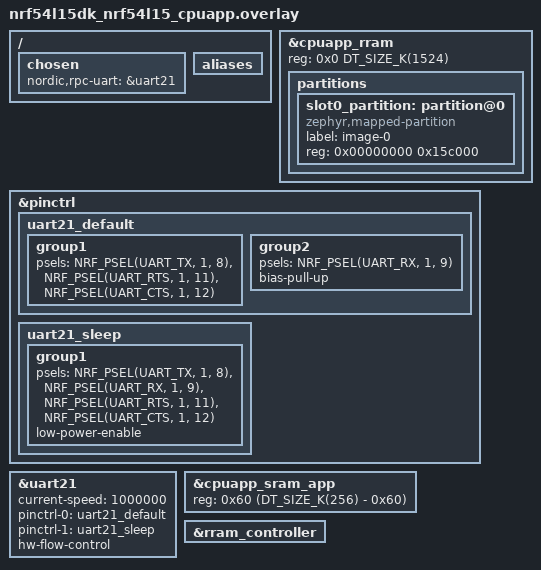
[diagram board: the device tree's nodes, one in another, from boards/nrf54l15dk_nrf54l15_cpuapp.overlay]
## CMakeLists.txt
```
#
# Copyright (c) 2024 Nordic Semiconductor ASA
#
# SPDX-License-Identifier: LicenseRef-Nordic-5-Clause
#
cmake_minimum_required(VERSION 3.20.0)

find_package(Zephyr REQUIRED HINTS $ENV{ZEPHYR_BASE})

project(protocols_serialization_client)

# NORDIC SDK APP START
target_sources(app PRIVATE
    src/main.c
)

zephyr_library_sources_ifdef(CONFIG_OPENTHREAD_RPC src/ot_shell.c)
zephyr_library_sources_ifdef(CONFIG_MPSL_CX_SOFTWARE src/coex_shell.c)
zephyr_library_sources_ifdef(CONFIG_LOG_FORWARDER_RPC src/log_rpc_shell.c)
zephyr_library_sources_ifdef(CONFIG_NFC_RPC src/nfc_shell.c)
zephyr_library_sources_ifdef(CONFIG_BT_THROUGHPUT src/bt_throughput_shell.c)
zephyr_library_sources_ifdef(CONFIG_NRF_RPC_UTILS src/rpc_utils_shell.c)
zephyr_library_sources_ifdef(CONFIG_NRF_PS_CLIENT_BT_TEST src/bt_test_shell.c)
# NORDIC SDK APP END
```

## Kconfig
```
#
# Copyright (c) 2024 Nordic Semiconductor ASA
#
# SPDX-License-Identifier: LicenseRef-Nordic-5-Clause
#

menu "Protocols serialization client"

config NRF_PS_CLIENT_CRASH_DUMP_READ_BUFFER_SIZE
	int "Crash log read buffer size"
	depends on LOG_FORWARDER_RPC
	default 256
	help
	  Size of the stack buffer used for reading a single chunk of the crash
	  log from the server device.

module = NRF_PS_CLIENT
module-str = nrf_ps_client
source "$(ZEPHYR_BASE)/subsys/logging/Kconfig.template.log_config"

config NRF_PS_CLIENT_BT_TEST
	bool "BLE test service for RPC Client"
	depends on BT
	help
	 Enable BLE test service for RPC Client.

if NRF_PS_CLIENT_BT_TEST

config NRF_PS_CLIENT_BT_TEST_CHAR_MAX_DATA_SIZE
	int "Maximum size of BLE test characteristic data in bytes"
	default 4

endif # NRF_PS_CLIENT_BT_TEST

endmenu # "Protocols serialization client"

if SETTINGS

config ZMS
	default y if (SOC_FLASH_NRF_RRAM || SOC_FLASH_NRF_MRAM)

config NVS
	default y if !(SOC_FLASH_NRF_RRAM || SOC_FLASH_NRF_MRAM)

endif # SETTINGS

menu "Zephyr Kernel"
source "Kconfig.zephyr"
endmenu
```

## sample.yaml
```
sample:
  name: Protocols serialization client sample
  description: Demonstrates serialization of Bluetooth LE and OpenThread API using
    nRF RPC

common:
  sysbuild: true
  build_only: true
  platform_allow:
    - nrf54l15dk/nrf54l15/cpuapp
    - nrf54lm20dk/nrf54lm20a/cpuapp
    - nrf54lm20dk/nrf54lm20b/cpuapp
  integration_platforms:
    - nrf54l15dk/nrf54l15/cpuapp
    - nrf54lm20dk/nrf54lm20a/cpuapp
    - nrf54lm20dk/nrf54lm20b/cpuapp
  tags:
    - ci_build
    - ci_samples_nrf_rpc
  extra_args:
    - SNIPPET_ROOT="."

tests:
  sample.nrf_rpc.protocols_serialization.client.rpc_ble:
    extra_args:
      - EXTRA_CONF_FILE=ble.conf
  sample.nrf_rpc.protocols_serialization.client.rpc_ot:
    extra_args:
      - EXTRA_CONF_FILE=openthread.conf
  sample.nrf_rpc.protocols_serialization.client.rpc:
    extra_args:
      - EXTRA_DTC_OVERLAY_FILE=coex.overlay
      - EXTRA_CONF_FILE="ble.conf;openthread.conf;verbose.conf;log_rpc.conf;coex.conf"
  sample.nrf_rpc.protocols_serialization.client.rpc_ci:
    extra_args:
      - SNIPPET="ci-shell;zperf"
      - EXTRA_DTC_OVERLAY_FILE=coex.overlay
      - EXTRA_CONF_FILE="ble.conf;openthread.conf;log_rpc.conf;coex.conf"
    extra_configs:
      - CONFIG_NRF_RPC_UTILS_CRASH_GEN=y
```

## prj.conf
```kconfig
#
# Copyright (c) 2024 Nordic Semiconductor
#
# SPDX-License-Identifier: LicenseRef-Nordic-5-Clause
#
CONFIG_HEAP_MEM_POOL_SIZE=4096

CONFIG_NRF_RPC=y
CONFIG_NRF_RPC_CBOR=y
CONFIG_NRF_RPC_ZCBOR_BACKUPS=1
CONFIG_NRF_RPC_THREAD_STACK_SIZE=4096
CONFIG_NRF_RPC_GROUP_INIT_WAIT_TIME=-1
CONFIG_NRF_RPC_UART_TRANSPORT=y
CONFIG_NRF_RPC_UART_RELIABLE=y

CONFIG_UART_LINE_CTRL=y
CONFIG_UART_INTERRUPT_DRIVEN=y

CONFIG_SHELL=y
CONFIG_SHELL_STACK_SIZE=3072
CONFIG_LOG=y
CONFIG_LOG_MODE_DEFERRED=y
CONFIG_LOG_BUFFER_SIZE=8192
CONFIG_LOG_FUNC_NAME_PREFIX_DBG=n
CONFIG_LOG_BACKEND_RTT=n
CONFIG_SHELL_LOG_BACKEND=y

CONFIG_NRF_RPC_UTILS=y
CONFIG_NRF_RPC_UTILS_CLIENT=y
CONFIG_NRF_RPC_UTILS_DEV_INFO=y
CONFIG_NRF_RPC_UTILS_REMOTE_SHELL=y
CONFIG_NRF_RPC_UTILS_SYSTEM_HEALTH=y
CONFIG_NRF_RPC_UTILS_NESTED_CMD_TEST=y

CONFIG_USE_DT_CODE_PARTITION=y
```

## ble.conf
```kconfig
#
# Copyright (c) 2024 Nordic Semiconductor ASA
#
# SPDX-License-Identifier: LicenseRef-Nordic-5-Clause
#

CONFIG_SYSTEM_WORKQUEUE_STACK_SIZE=2144

# Enable and configure Bluetooth LE
CONFIG_BT=y
CONFIG_BT_RPC_STACK=y
CONFIG_NRF_RPC_INIT=n
CONFIG_BT_RPC_GATT_SRV_MAX=4
CONFIG_BT_PERIPHERAL=y
CONFIG_BT_MAX_CONN=1
CONFIG_BT_LL_SOFTDEVICE=n
CONFIG_BT_SHELL=y

# Device name and appearance shall be the same as on the server side
CONFIG_BT_DEVICE_NAME="Nordic_PS"

# Enable the NUS service
CONFIG_BT_NUS=y
CONFIG_BT_NUS_LOG_LEVEL_DBG=y

# Enable the Latency service
CONFIG_BT_LATENCY=y
CONFIG_BT_LATENCY_LOG_LEVEL_DBG=y

# Enable the Test service
CONFIG_NRF_PS_CLIENT_BT_TEST=y

# Enable the Throughput service
CONFIG_BT_THROUGHPUT=y
CONFIG_BT_THROUGHPUT_LOG_LEVEL_DBG=y

# Enable SMP that is required by the Throughput service.
CONFIG_SETTINGS=y
CONFIG_FLASH=y
CONFIG_FLASH_MAP=y
CONFIG_BT_SETTINGS=y
CONFIG_BT_SMP=y

# Disable HCI-based entropy driver (unavailable for BT_RPC_STACK)
CONFIG_ENTROPY_BT_HCI=n
```

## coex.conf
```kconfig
#
# Copyright (c) 2024 Nordic Semiconductor ASA
#
# SPDX-License-Identifier: LicenseRef-Nordic-5-Clause
#

CONFIG_MPSL_CX=y
CONFIG_MPSL_CX_SOFTWARE=y
```

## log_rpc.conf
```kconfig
#
# Copyright (c) 2024 Nordic Semiconductor ASA
#
# SPDX-License-Identifier: LicenseRef-Nordic-5-Clause
#

CONFIG_LOG_FORWARDER_RPC=y
```

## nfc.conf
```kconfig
#
# Copyright (c) 2024 Nordic Semiconductor ASA
#
# SPDX-License-Identifier: LicenseRef-Nordic-5-Clause
#

CONFIG_NFC_RPC=y
CONFIG_NFC_RPC_CLIENT=y

CONFIG_NFC_NDEF=y
CONFIG_NFC_NDEF_MSG=y
CONFIG_NFC_NDEF_RECORD=y
CONFIG_NFC_NDEF_TEXT_RECORD=y
```

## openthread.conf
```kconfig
#
# Copyright (c) 2024 Nordic Semiconductor ASA
#
# SPDX-License-Identifier: LicenseRef-Nordic-5-Clause
#

CONFIG_OPENTHREAD_RPC=y
CONFIG_OPENTHREAD_RPC_CLIENT=y
CONFIG_OPENTHREAD_MESH_DIAG=y

CONFIG_NETWORKING=y
CONFIG_NET_IF_UNICAST_IPV6_ADDR_COUNT=6

# Enable networking shell to test the network interface operation
CONFIG_NET_SHELL=y
```

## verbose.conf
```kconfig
#
# Copyright (c) 2024 Nordic Semiconductor ASA
#
# SPDX-License-Identifier: LicenseRef-Nordic-5-Clause
#
# Development-oriented options: asserts and DBG log levels for this sample and
# nRF RPC modules. For manual use, pass e.g.:
#   -- -DEXTRA_CONF_FILE=verbose.conf

# Enable asserts
CONFIG_ASSERT=y

# Enable verbose logging
CONFIG_NRF_PS_CLIENT_LOG_LEVEL_DBG=y
CONFIG_NRF_RPC_TR_LOG_LEVEL_DBG=y
CONFIG_NRF_RPC_LOG_LEVEL_DBG=y
CONFIG_NRF_RPC_OS_LOG_LEVEL_DBG=y
CONFIG_NRF_RPC_DETAILED_ERROR_REPORTING=y
CONFIG_NRF_RPC_UTILS_RRAM_WEAR_TEST=y
```

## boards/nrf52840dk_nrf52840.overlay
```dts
/* Copyright (c) 2024 Nordic Semiconductor ASA
 *
 * SPDX-License-Identifier: LicenseRef-Nordic-5-Clause
 */

/ {
	chosen {
		nordic,rpc-uart = &uart1;
	};
};

/delete-node/ &boot_partition;
/delete-node/ &slot0_partition;
/delete-node/ &slot1_partition;

&flash0 {
	partitions {
		slot0_partition: partition@0 {
			compatible = "zephyr,mapped-partition";
			label = "image-0";
			reg = <0x00000000 0xf8000>;
		};
	};
};

&uart1 {
	status = "okay";
	hw-flow-control;
	current-speed = <1000000>;
};

&uart1_default {
	group1 {
		psels = <NRF_PSEL(UART_TX, 1, 2)>,
			<NRF_PSEL(UART_RTS, 1, 3)>,
			<NRF_PSEL(UART_CTS, 1, 4)>;
	};

	group2 {
		psels = <NRF_PSEL(UART_RX, 1, 1)>;
		bias-pull-up;
	};
};

&uart1_sleep {
	group1 {
		psels = <NRF_PSEL(UART_RX, 1, 1)>,
			<NRF_PSEL(UART_TX, 1, 2)>,
			<NRF_PSEL(UART_RTS, 1, 3)>,
			<NRF_PSEL(UART_CTS, 1, 4)>;
		low-power-enable;
	};
};
```

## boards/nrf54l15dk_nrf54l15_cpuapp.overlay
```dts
/* Copyright (c) 2024 Nordic Semiconductor ASA
 *
 * SPDX-License-Identifier: LicenseRef-Nordic-5-Clause
 */

/ {
	chosen {
		nordic,rpc-uart = &uart21;
	};

	/* delete all buttons except button0 to free GPIO pins assigned to uart21 below */
	aliases {
		/delete-property/ sw1;
		/delete-property/ sw2;
		/delete-property/ sw3;
	};
};

/delete-node/ &button1;
/delete-node/ &button2;
/delete-node/ &button3;
/delete-node/ &boot_partition;
/delete-node/ &slot0_partition;
/delete-node/ &slot1_partition;

/* restore full RRAM and SRAM space - by default some parts are dedicated to FLRP */
&cpuapp_rram {
	reg = <0x0 DT_SIZE_K(1524)>;

	partitions {
		slot0_partition: partition@0 {
			compatible = "zephyr,mapped-partition";
			label = "image-0";
			reg = <0x00000000 0x15c000>;
		};
	};
};

&pinctrl {
	uart21_default: uart21_default {
		group1 {
			psels = <NRF_PSEL(UART_TX, 1, 8)>,
				<NRF_PSEL(UART_RTS, 1, 11)>,
				<NRF_PSEL(UART_CTS, 1, 12)>;
		};

		group2 {
			psels = <NRF_PSEL(UART_RX, 1, 9)>;
			bias-pull-up;
		};
	};

	uart21_sleep: uart21_sleep {
		group1 {
			psels = <NRF_PSEL(UART_TX, 1, 8)>,
				<NRF_PSEL(UART_RX, 1, 9)>,
				<NRF_PSEL(UART_RTS, 1, 11)>,
				<NRF_PSEL(UART_CTS, 1, 12)>;
			low-power-enable;
		};
	};
};

&uart21 {
	status = "okay";
	current-speed = <1000000>;
	pinctrl-0 = <&uart21_default>;
	pinctrl-1 = <&uart21_sleep>;
	pinctrl-names = "default", "sleep";
	hw-flow-control;
};

&cpuapp_sram_app {
	reg = <0x60 (DT_SIZE_K(256) - 0x60)>;
};

&rram_controller {
	/delete-node/ cpuflpr_sram;
	/delete-node/ cpuflpr_rram;
};
```

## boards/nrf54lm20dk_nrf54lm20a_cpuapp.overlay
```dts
/* Copyright (c) 2025 Nordic Semiconductor ASA
 *
 * SPDX-License-Identifier: LicenseRef-Nordic-5-Clause
 */

/ {
	chosen {
		nordic,rpc-uart = &uart21;
	};

	/* delete all buttons except button0 to free GPIO pins assigned to uart21 below */
	aliases {
		/delete-property/ sw1;
		/delete-property/ sw2;
		/delete-property/ sw3;
	};
};

/delete-node/ &button1;
/delete-node/ &button2;
/delete-node/ &button3;
/delete-node/ &boot_partition;
/delete-node/ &slot0_partition;
/delete-node/ &slot1_partition;

&cpuapp_rram {
	reg = <0x0 DT_SIZE_K(2036)>;

	partitions {
		slot0_partition: partition@0 {
			compatible = "zephyr,mapped-partition";
			label = "image-0";
			reg = <0x00000000 0x1dc000>;
		};
	};
};

&pinctrl {
	uart21_default: uart21_default {
		group1 {
			psels = <NRF_PSEL(UART_TX, 1, 8)>,
				<NRF_PSEL(UART_RTS, 1, 11)>,
				<NRF_PSEL(UART_CTS, 1, 12)>;
		};

		group2 {
			psels = <NRF_PSEL(UART_RX, 1, 9)>;
			bias-pull-up;
		};
	};

	uart21_sleep: uart21_sleep {
		group1 {
			psels = <NRF_PSEL(UART_TX, 1, 8)>,
				<NRF_PSEL(UART_RX, 1, 9)>,
				<NRF_PSEL(UART_RTS, 1, 11)>,
				<NRF_PSEL(UART_CTS, 1, 12)>;
			low-power-enable;
		};
	};
};

&uart21 {
	status = "okay";
	current-speed = <1000000>;
	pinctrl-0 = <&uart21_default>;
	pinctrl-1 = <&uart21_sleep>;
	pinctrl-names = "default", "sleep";
	hw-flow-control;
};
```

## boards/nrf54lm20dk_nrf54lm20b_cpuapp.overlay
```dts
/* Copyright (c) 2026 Nordic Semiconductor ASA
 *
 * SPDX-License-Identifier: LicenseRef-Nordic-5-Clause
 */

/ {
	chosen {
		nordic,rpc-uart = &uart21;
	};

	/* delete all buttons except button0 to free GPIO pins assigned to uart21 below */
	aliases {
		/delete-property/ sw1;
		/delete-property/ sw2;
		/delete-property/ sw3;
	};
};

/delete-node/ &button1;
/delete-node/ &button2;
/delete-node/ &button3;
/delete-node/ &boot_partition;
/delete-node/ &slot0_partition;
/delete-node/ &slot1_partition;

&cpuapp_rram {
	reg = <0x0 DT_SIZE_K(2036)>;

	partitions {
		slot0_partition: partition@0 {
			label = "image-0";
			reg = <0x00000000 0x1dc000>;
		};
	};
};

&pinctrl {
	uart21_default: uart21_default {
		group1 {
			psels = <NRF_PSEL(UART_TX, 1, 8)>,
				<NRF_PSEL(UART_RTS, 1, 11)>,
				<NRF_PSEL(UART_CTS, 1, 12)>;
		};

		group2 {
			psels = <NRF_PSEL(UART_RX, 1, 9)>;
			bias-pull-up;
		};
	};

	uart21_sleep: uart21_sleep {
		group1 {
			psels = <NRF_PSEL(UART_TX, 1, 8)>,
				<NRF_PSEL(UART_RX, 1, 9)>,
				<NRF_PSEL(UART_RTS, 1, 11)>,
				<NRF_PSEL(UART_CTS, 1, 12)>;
			low-power-enable;
		};
	};
};

&uart21 {
	status = "okay";
	current-speed = <1000000>;
	pinctrl-0 = <&uart21_default>;
	pinctrl-1 = <&uart21_sleep>;
	pinctrl-names = "default", "sleep";
	hw-flow-control;
};
```

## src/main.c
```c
/*
 * Copyright (c) 2024 Nordic Semiconductor ASA
 *
 * SPDX-License-Identifier: LicenseRef-Nordic-5-Clause
 */

#include "ot_shell.h"

#include <zephyr/logging/log.h>

#include <nrf_rpc.h>

LOG_MODULE_REGISTER(nrf_ps_client, CONFIG_NRF_PS_CLIENT_LOG_LEVEL);
NRF_RPC_GROUP_DECLARE(ot_group);
NRF_RPC_GROUP_DECLARE(bt_rpc_grp);

static void err_handler(const struct nrf_rpc_err_report *report)
{
	LOG_ERR("nRF RPC error %d ocurred. See nRF RPC logs for more details", report->code);
}

static void bound_handler(const struct nrf_rpc_group *group)
{
#ifdef CONFIG_OPENTHREAD_RPC_CLIENT
	static bool ot_group_initialized;

	if (group == &ot_group) {
		if (ot_group_initialized) {
			LOG_WRN("OT RPC peer reset detected");
			ot_shell_server_restarted();
			/* The code to restore the state of OT on the server can be added here */
		} else {
			ot_group_initialized = true;
		}
	}
#endif
#ifdef CONFIG_BT_RPC_CLIENT
	static bool bt_group_initialized;

	if (group == &bt_rpc_grp) {
		if (bt_group_initialized) {
			LOG_WRN("BT RPC peer reset detected");
			/* The code to restore the state of BT on the server can be added here */
		} else {
			bt_group_initialized = true;
		}
	}
#endif
}

int main(void)
{
	int ret;

	LOG_INF("Initializing RPC client");

	nrf_rpc_set_bound_handler(bound_handler);

	ret = nrf_rpc_init(err_handler);

	if (ret != 0) {
		LOG_ERR("RPC init failed");
	}

	LOG_INF("RPC client ready");

	return 0;
}
```

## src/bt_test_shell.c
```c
/*
 * Copyright (c) 2025 Nordic Semiconductor ASA
 *
 * SPDX-License-Identifier: LicenseRef-Nordic-5-Clause
 */

#include <errno.h>
#include <stddef.h>
#include <zephyr/bluetooth/bluetooth.h>
#include <zephyr/bluetooth/conn.h>
#include <zephyr/bluetooth/gap.h>
#include <zephyr/bluetooth/gatt.h>
#include <zephyr/bluetooth/hci.h>
#include <zephyr/bluetooth/uuid.h>
#include <zephyr/shell/shell.h>
#include <zephyr/sys/__assert.h>
#include <zephyr/sys/byteorder.h>
#include <zephyr/sys/util.h>
#include <zephyr/types.h>
#include <zephyr/logging/log.h>

LOG_MODULE_REGISTER(bt_test, CONFIG_NRF_PS_CLIENT_LOG_LEVEL);

/* UUID: 12345678-1234-5678-1234-56789abcdef0 */
#define BT_UUID_CUSTOM_SERVICE_VAL                                                                 \
	BT_UUID_128_ENCODE(0x12345678, 0x1234, 0x5678, 0x1234, 0x56789abcdef0)
#define BT_UUID_CUSTOM_CHAR_VAL                                                                    \
	BT_UUID_128_ENCODE(0xabcdef01, 0x2345, 0x6789, 0xabcd, 0xef0123456789)

#ifdef CONFIG_NRF_PS_CLIENT_BT_TEST_DATA_SIZE
#define TEST_DATA_SIZE (CONFIG_NRF_PS_CLIENT_BT_TEST_DATA_SIZE)
#else
#define TEST_DATA_SIZE (10)
#endif

static void connected(struct bt_conn *conn, uint8_t hci_err);
static void disconnected(struct bt_conn *conn, uint8_t reason);
static void update_subscribed(void);
static void ccc_cfg_changed(const struct bt_gatt_attr *attr, uint16_t value);
static ssize_t read_custom_char(struct bt_conn *conn, const struct bt_gatt_attr *attr, void *buf,
				uint16_t len, uint16_t offset);
static ssize_t write_custom_char(struct bt_conn *conn, const struct bt_gatt_attr *attr,
				 const void *buf, uint16_t len, uint16_t offset, uint8_t flags);

static const struct bt_data ad[] = {
	BT_DATA_BYTES(BT_DATA_FLAGS, BT_LE_AD_GENERAL | BT_LE_AD_NO_BREDR),
	BT_DATA_BYTES(BT_DATA_UUID128_ALL, BT_UUID_CUSTOM_SERVICE_VAL),
};

static const struct bt_data sd[] = {
	BT_DATA(BT_DATA_NAME_COMPLETE, CONFIG_BT_DEVICE_NAME, sizeof(CONFIG_BT_DEVICE_NAME) - 1),
};

static struct bt_uuid_128 custom_service_uuid = BT_UUID_INIT_128(BT_UUID_CUSTOM_SERVICE_VAL);
static struct bt_uuid_128 custom_char_uuid = BT_UUID_INIT_128(BT_UUID_CUSTOM_CHAR_VAL);

static struct bt_gatt_indicate_params ind_params;

static struct bt_conn_cb conn_cb = {
	.connected = connected,
	.disconnected = disconnected,
};

typedef struct {
	uint8_t data[TEST_DATA_SIZE];
	bool notify_enabled;
	bool indicate_enabled;
	struct bt_conn *conn;
} test_svc_ctx_t;

static test_svc_ctx_t test_ctx = {
	.data = {},
	.notify_enabled = false,
	.indicate_enabled = false,
	.conn = NULL,
};

BT_GATT_SERVICE_DEFINE(custom_svc, BT_GATT_PRIMARY_SERVICE(&custom_service_uuid),
		       BT_GATT_CHARACTERISTIC(&custom_char_uuid.uuid,
					      BT_GATT_CHRC_READ | BT_GATT_CHRC_WRITE |
						      BT_GATT_CHRC_NOTIFY | BT_GATT_CHRC_INDICATE,
					      BT_GATT_PERM_READ | BT_GATT_PERM_WRITE,
					      read_custom_char, write_custom_char, &test_ctx),
		       BT_GATT_CCC(ccc_cfg_changed, BT_GATT_PERM_READ | BT_GATT_PERM_WRITE));

static ssize_t read_custom_char(struct bt_conn *conn, const struct bt_gatt_attr *attr, void *buf,
				uint16_t len, uint16_t offset)
{
	test_svc_ctx_t *ctx = attr->user_data;
	uint16_t actual_len = MIN(len, TEST_DATA_SIZE - offset);

	LOG_INF("BT Test Read. off %d len %d", offset, len);

	if (offset >= TEST_DATA_SIZE) {
		LOG_ERR("BT Test Invalid offset");
		return BT_GATT_ERR(BT_ATT_ERR_INVALID_OFFSET);
	}

	LOG_HEXDUMP_INF(ctx->data, TEST_DATA_SIZE, "BT Test State of data");
	LOG_HEXDUMP_INF(ctx->data + offset, actual_len, "BT Test Read:");

	return bt_gatt_attr_read(conn, attr, buf, len, offset, ctx->data, TEST_DATA_SIZE);
}

static ssize_t write_custom_char(struct bt_conn *conn, const struct bt_gatt_attr *attr,
				 const void *buf, uint16_t len, uint16_t offset, uint8_t flags)
{
	test_svc_ctx_t *ctx = attr->user_data;
	uint16_t actual_len = MIN(len, TEST_DATA_SIZE - offset);

	if (offset >= TEST_DATA_SIZE) {
		LOG_ERR("BT Test Invalid offset");
		return BT_GATT_ERR(BT_ATT_ERR_INVALID_OFFSET);
	}

	if (actual_len < len) {
		LOG_ERR("BT Test Write length exceeds the size of the data. requested %d, max %d",
			len, TEST_DATA_SIZE);
		return BT_GATT_ERR(BT_ATT_ERR_INVALID_ATTRIBUTE_LEN);
	}

	memcpy(ctx->data + offset, buf, actual_len);
	LOG_INF("BT Test write data at offset %d", offset);
	LOG_HEXDUMP_INF(buf, actual_len, "BT Test write data");
	LOG_HEXDUMP_INF(ctx->data, TEST_DATA_SIZE, "BT Test Final state of data after write");
	update_subscribed();
	return actual_len;
}

static void ccc_cfg_changed(const struct bt_gatt_attr *attr, uint16_t value)
{
	test_ctx.notify_enabled = (value & BT_GATT_CCC_NOTIFY) != 0;
	test_ctx.indicate_enabled = (value & BT_GATT_CCC_INDICATE) != 0;
	LOG_INF("BT Test Notify: %s, Indicate: %s", test_ctx.notify_enabled ? "ON" : "OFF",
		test_ctx.indicate_enabled ? "ON" : "OFF");
}

static void indicate_cb(struct bt_conn *conn, struct bt_gatt_indicate_params *params, uint8_t err)
{
	if (err) {
		LOG_ERR("BT Test Indication confirmation error: %d", err);
		return;
	}

	LOG_INF("BT Test Indication confirmed by client");
}

static void update_subscribed(void)
{
	int err = -ENOENT;

	if (test_ctx.conn && test_ctx.notify_enabled) {
		err = bt_gatt_notify(test_ctx.conn, &custom_svc.attrs[1], test_ctx.data,
				     TEST_DATA_SIZE);
		if (err) {
			LOG_ERR("BT Test Notify error: %d", err);
		} else {
			LOG_HEXDUMP_INF(test_ctx.data, TEST_DATA_SIZE, "BT Test Notified:");
		}
	}
	if (test_ctx.conn && test_ctx.indicate_enabled) {
		ind_params.attr = &custom_svc.attrs[1];
		ind_params.func = indicate_cb;
		ind_params.data = test_ctx.data;
		ind_params.len = TEST_DATA_SIZE;
		ind_params.destroy = NULL;
		err = bt_gatt_indicate(test_ctx.conn, &ind_params);
		if (err) {
			LOG_ERR("BT Test Indicate error: %d", err);
		} else {
			LOG_HEXDUMP_INF(test_ctx.data, TEST_DATA_SIZE, "BT Test Indication sent:");
		}
	}
}

static void connected(struct bt_conn *conn, uint8_t hci_err)
{
	if (hci_err) {
		LOG_ERR("BT Test Connected error: %d", hci_err);
		return;
	}
	test_ctx.conn = conn;
	LOG_INF("BT Test Connected");
}

static void disconnected(struct bt_conn *conn, uint8_t reason)
{
	ARG_UNUSED(conn);
	test_ctx.conn = NULL;
	test_ctx.notify_enabled = false;
	test_ctx.indicate_enabled = false;
	LOG_INF("BT Test Disconnected, reason: %d", reason);
}

static int advertise(void)
{
	int err;
	(void)bt_conn_cb_register(&conn_cb);
	err = bt_le_adv_start(BT_LE_ADV_CONN_FAST_2, ad, ARRAY_SIZE(ad), sd, ARRAY_SIZE(sd));
	if (err) {
		(void)bt_conn_cb_unregister(&conn_cb);
	}
	return err;
}

static int cmd_advertise(const struct shell *sh, size_t argc, char *argv[])
{
	bool start;
	int err;

	if (!strcmp(argv[1], "on")) {
		start = true;
	} else if (!strcmp(argv[1], "off")) {
		start = false;
	} else {
		shell_error(sh, "BT Test Invalid argument: %s", argv[1]);
		return -EINVAL;
	}
	if (start) {
		err = advertise();
	} else {
		err = bt_le_adv_stop();
		(void)bt_conn_cb_unregister(&conn_cb);
	}
	if (err < 0) {
		shell_error(sh, "BT Test Failed to %s advertising: %d", start ? "start" : "stop",
			    err);
		return -ENOEXEC;
	}
	shell_print(sh, "BT Test Advertising %s", start ? "started" : "stopped");
	return 0;
}

static int cmd_read(const struct shell *sh, size_t argc, char *argv[])
{
	ARG_UNUSED(argc);
	ARG_UNUSED(argv);

	shell_hexdump(sh, test_ctx.data, TEST_DATA_SIZE);
	shell_print(sh, "BT Test Read Characteristic value");
	return 0;
}

static int cmd_write(const struct shell *sh, size_t argc, char *argv[])
{
	uint8_t value[TEST_DATA_SIZE] = {0};
	size_t len = 0;
	size_t len_hex = 0;

	if (argc < 2) {
		shell_error(sh, "BT Test Usage: write <hex_value>");
		return -EINVAL;
	}

	/* Limit the length of the hex value to the size of the data */
	len_hex = strnlen(argv[1], (TEST_DATA_SIZE * 2) + 1);

	if (len_hex > TEST_DATA_SIZE * 2) {
		shell_error(sh, "BT Test Write length exceeds the size of the data");
		return -EINVAL;
	}

	len = hex2bin(argv[1], len_hex, value, sizeof(value));
	if (len == 0) {
		shell_error(sh, "BT Test Failed to parse hex value: %s", argv[1]);
		return -EINVAL;
	}

	memcpy(test_ctx.data, value, len);
	shell_hexdump(sh, test_ctx.data, TEST_DATA_SIZE);
	shell_print(sh, "BT Test Wrote characteristic value");
	update_subscribed();

	return 0;
}

SHELL_STATIC_SUBCMD_SET_CREATE(
	bt_test_cmds, SHELL_CMD_ARG(advertise, NULL, "on|off", cmd_advertise, 2, 0),
	SHELL_CMD_ARG(read, NULL, "Read characteristic value", cmd_read, 1, 0),
	SHELL_CMD_ARG(write, NULL, "Write characteristic value <hex>", cmd_write, 2, 0),
	SHELL_SUBCMD_SET_END);

SHELL_CMD_ARG_REGISTER(bt_test, &bt_test_cmds, "BLE test service commands", NULL, 2, 0);
```

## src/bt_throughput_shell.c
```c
/*
 * Copyright (c) 2025 Nordic Semiconductor ASA
 *
 * SPDX-License-Identifier: LicenseRef-Nordic-5-Clause
 */

#include <bluetooth/services/throughput.h>

#include <zephyr/bluetooth/bluetooth.h>
#include <zephyr/bluetooth/conn.h>
#include <zephyr/shell/shell.h>
#include <zephyr/sys/__assert.h>

static const struct bt_data ad[] = {
	BT_DATA_BYTES(BT_DATA_FLAGS, BT_LE_AD_GENERAL | BT_LE_AD_NO_BREDR),
	BT_DATA_BYTES(BT_DATA_UUID128_ALL, BT_UUID_THROUGHPUT_VAL),
};

static const struct bt_data sd[] = {
	BT_DATA(BT_DATA_NAME_COMPLETE, CONFIG_BT_DEVICE_NAME, sizeof(CONFIG_BT_DEVICE_NAME) - 1),
};

static int advertise(void);

static void connected(struct bt_conn *conn, uint8_t hci_err)
{
	int rc;

	if (hci_err) {
		return;
	}

	rc = bt_conn_set_security(conn, BT_SECURITY_L2);
	__ASSERT(rc == 0, "Failed to set BLE security level: %d", rc);
}

static void disconnected(struct bt_conn *conn, uint8_t reason)
{
	ARG_UNUSED(conn);
	ARG_UNUSED(reason);

	advertise();
}

static struct bt_conn_cb conn_cb = {
	.connected = connected,
	.disconnected = disconnected,
};

static int advertise(void)
{
	int rc;

	(void)bt_conn_cb_register(&conn_cb);
	rc = bt_le_adv_start(BT_LE_ADV_CONN_FAST_2, ad, ARRAY_SIZE(ad), sd, ARRAY_SIZE(sd));

	if (rc) {
		(void)bt_conn_cb_unregister(&conn_cb);
	}

	return rc;
}

static int cmd_advertise(const struct shell *sh, size_t argc, char *argv[])
{
	bool start;
	int rc;

	if (!strcmp(argv[1], "on")) {
		start = true;
	} else if (!strcmp(argv[1], "off")) {
		start = false;
	} else {
		shell_error(sh, "Invalid argument: %s", argv[1]);
		return -EINVAL;
	}

	if (start) {
		rc = advertise();
	} else {
		rc = bt_le_adv_stop();
		(void)bt_conn_cb_unregister(&conn_cb);
	}

	if (rc < 0) {
		shell_error(sh, "Failed to %s advertising: %d", start ? "start" : "stop", rc);
		return -ENOEXEC;
	}

	shell_print(sh, "Advertising %s", start ? "started" : "stopped");
	return 0;
}

SHELL_STATIC_SUBCMD_SET_CREATE(bt_throughput_cmds,
			       SHELL_CMD_ARG(advertise, NULL, "on|off", cmd_advertise, 2, 0),
			       SHELL_SUBCMD_SET_END);

SHELL_CMD_ARG_REGISTER(bt_throughput, &bt_throughput_cmds, "BLE throughput commands", NULL, 2, 0);
```

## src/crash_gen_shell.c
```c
#include <zephyr/shell/shell.h>
#include <nrf_rpc/nrf_rpc_dev_info.h>

static int cmd_assert(const struct shell *sh, size_t argc, char *argv[])
{
	int rc = 0;
	uint32_t delay = 0;

	if (argc > 1) {
		delay = shell_strtol(argv[1], 10, &rc);
	}

	if (rc) {
		shell_print(sh, "Invalid argument: %s", argv[1]);
		return -EINVAL;
	}

        nrf_rpc_crash_gen_assert(delay);

        return 0;
}

static int cmd_hard_fault(const struct shell *sh, size_t argc, char *argv[])
{
	int rc = 0;
	uint32_t delay = 0;

	if (argc > 1) {
		delay = shell_strtol(argv[1], 10, &rc);
	}

	if (rc) {
		shell_print(sh, "Invalid argument: %s", argv[1]);
		return -EINVAL;
	}

        nrf_rpc_crash_gen_hard_fault(delay);

        return 0;
}

static int cmd_stack_overflow(const struct shell *sh, size_t argc, char *argv[])
{
	int rc = 0;
	uint32_t delay = 0;

	if (argc > 1) {
		delay = shell_strtol(argv[1], 10, &rc);
	}

	if (rc) {
		shell_print(sh, "Invalid argument: %s", argv[1]);
		return -EINVAL;
	}

        nrf_rpc_crash_gen_stack_overflow(delay);

        return 0;
}

SHELL_STATIC_SUBCMD_SET_CREATE(crash_cmds,
			       SHELL_CMD_ARG(assert, NULL, "Invoke assert", cmd_assert, 1, 1),
			       SHELL_CMD_ARG(hard_fault, NULL, "Invoke hard fault", cmd_hard_fault,
			       		     1, 1),
			       SHELL_CMD_ARG(stack_overflow, NULL, "Invoke stack overflow",
			       		     cmd_stack_overflow, 1, 1),
			       SHELL_SUBCMD_SET_END);

SHELL_CMD_ARG_REGISTER(crash_gen, &crash_cmds, "nRF RPC crash generator commands", NULL, 1, 0);
```

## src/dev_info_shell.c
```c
/*
 * Copyright (c) 2024 Nordic Semiconductor ASA
 *
 * SPDX-License-Identifier: LicenseRef-Nordic-5-Clause
 */

#include <zephyr/shell/shell.h>
#include <nrf_rpc/nrf_rpc_dev_info.h>

static int remote_version_cmd(const struct shell *sh, size_t argc, char *argv[])
{
	char *version = nrf_rpc_get_ncs_commit_sha();

	if (!version) {
		shell_error(sh, "Failed to get remote version");
		return -ENOEXEC;
	}

	shell_print(sh, "Remote version: %s", version);

	k_free(version);

	return 0;
}

static int remote_shell_cmd(const struct shell *sh, size_t argc, char *argv[])
{
	char *output = nrf_rpc_invoke_remote_shell_cmd(argc - 1, argv + 1);

	if (!output) {
		shell_error(sh, "Failed to invoke remote shell command");
		return -ENOEXEC;
	}

	shell_print(sh, "%s", output);

	k_free(output);

	return 0;
}

SHELL_STATIC_SUBCMD_SET_CREATE(util_cmds,
			       SHELL_CMD_ARG(remote_version, NULL, "Get server version",
					     remote_version_cmd, 1, 0),
			       SHELL_CMD_ARG(remote_shell, NULL, "Call remote shell command",
					     remote_shell_cmd, 2, 255),
			       SHELL_SUBCMD_SET_END);

SHELL_CMD_ARG_REGISTER(rpc, &util_cmds, "nRF RPC utility commands", NULL, 1, 0);
```

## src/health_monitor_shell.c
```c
/*
 * Copyright (c) 2025 Nordic Semiconductor ASA
 *
 * SPDX-License-Identifier: LicenseRef-Nordic-5-Clause
 */
#include <zephyr/kernel.h>
#include <zephyr/logging/log.h>
#include <zephyr/shell/shell.h>

#include <health_monitor.h>

LOG_MODULE_REGISTER(nrf_ps_client_healthmon, CONFIG_NRF_PS_CLIENT_LOG_LEVEL);

#define EVENT_LOG_SIZE 5

const char *event_names[HEALTH_EVENT__COUNT] = {
	"INVALID",
	"BUFFERS_LOW",
	"DISCONNECTED",
	"SRP_REG",
	"NO_PREFIX",
	"WEAK_SIGNAL",
	"NO_NEIGHBORS",
	"STATS"
};

static struct counters_data last_monitor_data;
static health_event_type_t last_events[EVENT_LOG_SIZE];
static uint8_t last_event_index;

static const char *event_name(health_event_type_t event)
{
	const char *name = "UNKNOWN";

	if (event < HEALTH_EVENT__COUNT) {
		return event_names[event];
	}

	return name;
}

static void add_event(health_event_type_t event)
{
	if (event != HEALTH_EVENT_STATS) {
		uint8_t new_index = (last_event_index + 1) % EVENT_LOG_SIZE;

		last_events[new_index] = event;
		last_event_index = new_index;
	}
}

static void health_monitor_event_handler(struct health_event_data *event, void *context)
{
	LOG_INF("received event %s", event_name(event->event_type));
	add_event(event->event_type);

	switch (event->event_type) {
	case HEALTH_EVENT_STATS:
		memcpy(&last_monitor_data, event->counters, sizeof(last_monitor_data));
		LOG_INF("Counter values:\n\r"
			"\tchild added:                       %u\n\r"
			"\tchild removed:                     %u\n\r"
			"\tpartition id changes:              %u\n\r"
			"\tkey sequence changes:              %u\n\r"
			"\tnetwork data changes:              %u\n\r"
			"\tactive dataset changes:            %u\n\r"
			"\tpending dataset changes:           %u\n\r"
			"\trole_disabled:                     %u\n\r"
			"\trole_detached:                     %u\n\r"
			"\trole_child:                        %u\n\r"
			"\trole_router:                       %u\n\r"
			"\trole_leader:                       %u\n\r"
			"\tattach_attempts:                   %u\n\r"
			"\tbetter_partition_attach_attempts:  %u\n\r"
			"\tip_tx_success:                     %u\n\r"
			"\tip_rx_success:                     %u\n\r"
			"\tip_tx_failure:                     %u\n\r"
			"\tip_rx_failure:                     %u\n\r"
			"\tmac_tx_total:                      %u\n\r"
			"\tmac_tx_unicast:                    %u\n\r"
			"\tmac_tx_broadcast:                  %u\n\r"
			"\tmac_tx_retry:                      %u\n\r"
			"\tmac_rx_total:                      %u\n\r"
			"\tmac_rx_unicast:                    %u\n\r"
			"\tmac_rx_broadcast:                  %u\n\r"
			"\tchild_supervision_failure:         %u\n\r"
			"\tchild_max:                         %u\n\r"
			"\trouter_max:                        %u\n\r"
			"\trouter_added:                      %u\n\r"
			"\trouter_removed:                    %u\n\r"
			"\tsrp_server_changes:                %u\n\r",
			(uint32_t)event->counters->child_added,
			(uint32_t)event->counters->child_removed,
			(uint32_t)event->counters->partition_id_changes,
			(uint32_t)event->counters->key_sequence_changes,
			(uint32_t)event->counters->network_data_changes,
			(uint32_t)event->counters->active_dataset_changes,
			(uint32_t)event->counters->pending_dataset_changes,
			(uint32_t)event->counters->role_disabled,
			(uint32_t)event->counters->role_detached,
			(uint32_t)event->counters->role_child,
			(uint32_t)event->counters->role_router,
			(uint32_t)event->counters->role_leader,
			(uint32_t)event->counters->attach_attempts,
			(uint32_t)event->counters->better_partition_attach_attempts,
			(uint32_t)event->counters->ip_tx_success,
			(uint32_t)event->counters->ip_rx_success,
			(uint32_t)event->counters->ip_tx_failure,
			(uint32_t)event->counters->ip_rx_failure,
			(uint32_t)event->counters->mac_tx_unicast +
			(uint32_t)event->counters->mac_tx_broadcast,
			(uint32_t)event->counters->mac_tx_unicast,
			(uint32_t)event->counters->mac_tx_broadcast,
			(uint32_t)event->counters->mac_tx_retry,
			(uint32_t)event->counters->mac_rx_unicast +
			(uint32_t)event->counters->mac_rx_broadcast,
			(uint32_t)event->counters->mac_rx_unicast,
			(uint32_t)event->counters->mac_rx_broadcast,
			(uint32_t)event->counters->child_supervision_failure,
			(uint32_t)event->counters->child_max,
			(uint32_t)event->counters->router_max,
			(uint32_t)event->counters->router_added,
			(uint32_t)event->counters->router_removed,
			(uint32_t)event->counters->srp_server_changes
		);
		break;
	case HEALTH_EVENT_NO_BUFFERS:
		LOG_INF("Buffers:\n\r"
			"\ttotal:           %u\n\r"
			"\tmax used:             %u\n\r"
			"\tcurren free:           %u\n\r",
			event->no_buffers.total_count,
			event->no_buffers.max_used,
			event->no_buffers.current_free);
		break;
	default:
		/* unknown or no args event. */
		break;
	}
}

static int cmd_healthmon_interval(const struct shell *sh, size_t argc, char *argv[])
{
	int rc = 0;
	uint32_t interval = 0;

	interval = shell_strtoul(argv[1], 10, &rc);

	if (rc) {
		shell_print(sh, "Invalid argument: %s", argv[1]);
		return -EINVAL;
	}

	health_monitor_set_raport_interval(interval);

	shell_print(sh, "Interval set to %u", interval);

	return 0;
}

static int cmd_healthmon_last(const struct shell *sh, size_t argc, char *argv[])
{
	shell_print(sh, "EVENTS:");
	uint8_t last_event = last_event_index;

	for (uint8_t index = last_event + EVENT_LOG_SIZE; index > last_event; index--) {
		health_event_type_t event = last_events[index % EVENT_LOG_SIZE];

		shell_print(sh, "\t%s(%d)", event_name(event), event);
	}

	shell_print(sh, "\n\rRAPORT:");
	shell_print(sh, "\tchild added:                       %u",
			(uint32_t)last_monitor_data.child_added);
	shell_print(sh, "\tchild removed:                     %u",
			(uint32_t)last_monitor_data.child_removed);
	shell_print(sh, "\tpartition id changes:              %u",
			(uint32_t)last_monitor_data.partition_id_changes);
	shell_print(sh, "\tkey sequence changes:              %u",
			(uint32_t)last_monitor_data.key_sequence_changes);
	shell_print(sh, "\tnetwork data changes:              %u",
			(uint32_t)last_monitor_data.network_data_changes);
	shell_print(sh, "\tactive dataset changes:            %u",
			(uint32_t)last_monitor_data.active_dataset_changes);
	shell_print(sh, "\tpending dataset changes:           %u",
			(uint32_t)last_monitor_data.pending_dataset_changes);
	shell_print(sh, "\trole_disabled:                     %u",
			(uint32_t)last_monitor_data.role_disabled);
	shell_print(sh, "\trole_detached:                     %u",
			(uint32_t)last_monitor_data.role_detached);
	shell_print(sh, "\trole_child:                        %u",
			(uint32_t)last_monitor_data.role_child);
	shell_print(sh, "\trole_router:                       %u",
			(uint32_t)last_monitor_data.role_router);
	shell_print(sh, "\trole_leader:                       %u",
			(uint32_t)last_monitor_data.role_leader);
	shell_print(sh, "\tattach_attempts:                   %u",
			(uint32_t)last_monitor_data.attach_attempts);
	shell_print(sh, "\tbetter_partition_attach_attempts:  %u",
			(uint32_t)last_monitor_data.better_partition_attach_attempts);
	shell_print(sh, "\tip_tx_success:                     %u",
			(uint32_t)last_monitor_data.ip_tx_success);
	shell_print(sh, "\tip_rx_success:                     %u",
			(uint32_t)last_monitor_data.ip_rx_success);
	shell_print(sh, "\tip_tx_failure:                     %u",
			(uint32_t)last_monitor_data.ip_tx_failure);
	shell_print(sh, "\tip_rx_failure:                     %u",
			(uint32_t)last_monitor_data.ip_rx_failure);
	shell_print(sh, "\tmac_tx_total:                      %u",
			(uint32_t)last_monitor_data.mac_tx_unicast +
			(uint32_t)last_monitor_data.mac_tx_broadcast);
	shell_print(sh, "\tmac_tx_unicast:                    %u",
			(uint32_t)last_monitor_data.mac_tx_unicast);
	shell_print(sh, "\tmac_tx_broadcast:                  %u",
			(uint32_t)last_monitor_data.mac_tx_broadcast);
	shell_print(sh, "\tmac_tx_retry:                      %u",
			(uint32_t)last_monitor_data.mac_tx_retry);
	shell_print(sh, "\tmac_rx_total:                      %u",
			(uint32_t)last_monitor_data.mac_rx_unicast +
			(uint32_t)last_monitor_data.mac_rx_broadcast);
	shell_print(sh, "\tmac_rx_unicast:                    %u",
			(uint32_t)last_monitor_data.mac_rx_unicast);
	shell_print(sh, "\tmac_rx_broadcast:                  %u",
			(uint32_t)last_monitor_data.mac_rx_broadcast);
	shell_print(sh, "\tchild_supervision_failure:         %u",
			(uint32_t)last_monitor_data.child_supervision_failure);
	shell_print(sh, "\tchild_max:                         %u",
			(uint32_t)last_monitor_data.child_max);
	shell_print(sh, "\trouter_max:                        %u",
			(uint32_t)last_monitor_data.router_max);
	shell_print(sh, "\trouter_added:                      %u",
			(uint32_t)last_monitor_data.router_added);
	shell_print(sh, "\trouter_removed:                    %u",
			(uint32_t)last_monitor_data.router_removed);
	shell_print(sh, "\tsrp_server_changes:                %u",
			(uint32_t)last_monitor_data.srp_server_changes);

	shell_print(sh, "done");

	return 0;
}

static int cmd_healthmon_register(const struct shell *sh, size_t argc, char *argv[])
{
	health_monitor_set_event_callback(health_monitor_event_handler, NULL);
	shell_print(sh, "Event handler registered.");
	return 0;
}

SHELL_STATIC_SUBCMD_SET_CREATE(
	healthmon_cmds,
	SHELL_CMD_ARG(interval, NULL, "Set the monitor interval",
		      cmd_healthmon_interval, 2, 0),
	SHELL_CMD_ARG(last, NULL, "Get last data reported by health monitor",
		      cmd_healthmon_last, 0, 0),
	SHELL_CMD_ARG(register, NULL, "Register for notification reception",
		      cmd_healthmon_register, 0, 0),
	SHELL_SUBCMD_SET_END);

SHELL_CMD_ARG_REGISTER(healthmon, &healthmon_cmds, "nRF RPC utility commands", NULL, 1, 0);
```

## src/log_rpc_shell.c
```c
/*
 * Copyright (c) 2024 Nordic Semiconductor ASA
 *
 * SPDX-License-Identifier: LicenseRef-Nordic-5-Clause
 */

#include <logging/log_rpc.h>

#include <zephyr/kernel.h>
#include <zephyr/shell/shell.h>
#include <zephyr/sys/util.h>

#include <stdlib.h>
#include <string.h>
#include <errno.h>

#define COREDUMP_LOG_PREFIX   "#CD:"
#define COREDUMP_LOG_BEGIN    "BEGIN#"
#define COREDUMP_LOG_END      "END#"
#define COREDUMP_LOG_LINE_LEN 32

#define HISTORY_DUMP_PREFIX   "#LH:"

/* Text payload format marker (server writes this at start of payload) */
#define HISTORY_DUMP_TEXT_MAGIC "LH02"
#define HISTORY_DUMP_TEXT_MAGIC_LEN 4

static int cmd_log_rpc_stream_level(const struct shell *sh, size_t argc, char *argv[])
{
	int rc = 0;
	enum log_rpc_level level;

	level = (enum log_rpc_level)shell_strtol(argv[1], 10, &rc);

	if (rc || level < LOG_RPC_LEVEL_NONE || level > LOG_RPC_LEVEL_DBG) {
		shell_error(sh, "Invalid argument: %d", rc);
		return -EINVAL;
	}

	log_rpc_set_stream_level(level);

	return 0;
}

static int cmd_log_rpc_history_level(const struct shell *sh, size_t argc, char *argv[])
{
	int rc = 0;
	enum log_rpc_level level;

	level = (enum log_rpc_level)shell_strtol(argv[1], 10, &rc);

	if (rc || level < LOG_RPC_LEVEL_NONE || level > LOG_RPC_LEVEL_DBG) {
		shell_error(sh, "Invalid argument: %d", rc);
		return -EINVAL;
	}

	log_rpc_set_history_level(level);

	return 0;
}

static const struct shell *shell;

static void history_handler(enum log_rpc_level level, const char *msg, size_t msg_len)
{
	enum shell_vt100_color color;

	if (!msg) {
		shell_print(shell, "Done");
		return;
	}

	switch (level) {
	case LOG_RPC_LEVEL_INF:
		color = SHELL_INFO;
		break;
	case LOG_RPC_LEVEL_WRN:
		color = SHELL_WARNING;
		break;
	case LOG_RPC_LEVEL_ERR:
		color = SHELL_ERROR;
		break;
	default:
		color = SHELL_NORMAL;
		break;
	}

	shell_fprintf(shell, color, "%.*s\n", msg_len, msg);
}

static int cmd_log_rpc_history_fetch(const struct shell *sh, size_t argc, char *argv[])
{
	int rc = 0;

	shell = sh;
	rc = log_rpc_fetch_history(history_handler);

	if (rc) {
		shell_error(sh, "Error: %d", rc);
		return -ENOEXEC;
	}

	return 0;
}

static int cmd_log_rpc_history_stop_fetch(const struct shell *sh, size_t argc, char *argv[])
{
	int rc = 0;
	bool pause;

	pause = shell_strtobool(argv[1], 0, &rc);

	if (rc) {
		shell_error(sh, "Invalid argument: %d", rc);
		return -EINVAL;
	}

	log_rpc_stop_fetch_history(pause);

	return 0;
}

static void history_threshold_reached_handler(void)
{
	shell_print(shell, "History usage threshold reached");
}

static int cmd_log_rpc_history_threshold(const struct shell *sh, size_t argc, char *argv[])
{
	uint32_t threshold;
	int rc = 0;

	if (argc == 1) {
		shell_print(sh, "%u", log_rpc_get_history_usage_threshold());
		return 0;
	}

	threshold = shell_strtoul(argv[1], 0, &rc);

	if (rc) {
		shell_error(sh, "Invalid argument: %d", rc);
		return -EINVAL;
	}

	if (threshold > 100) {
		shell_error(sh, "%u exceeds max value (100)", threshold);
		return -EINVAL;
	}

	shell = sh;
	log_rpc_set_history_usage_threshold(history_threshold_reached_handler, (uint8_t)threshold);
	shell_print(sh, "%u", log_rpc_get_history_usage_threshold());

	return 0;
}

static int cmd_log_rpc_history_usage_current(const struct shell *sh, size_t argc, char *argv[])
{
	size_t usage_size;
	size_t max_size;
	size_t usage;

	usage_size = log_rpc_get_history_usage_current();
	max_size = log_rpc_get_history_usage_max();
	usage = (usage_size * 100 + max_size / 2) / max_size;
	shell_print(sh,
		    "History usage size: %zu bytes, max size: %zu bytes, usage: %zu%%",
		    usage_size, max_size, usage);

	return 0;
}

static int cmd_log_rpc_crash(const struct shell *sh, size_t argc, char *argv[])
{
	int rc;
	char buffer[CONFIG_NRF_PS_CLIENT_CRASH_DUMP_READ_BUFFER_SIZE];
	char line[COREDUMP_LOG_LINE_LEN * 2 + 1];
	size_t offset = 0;

	shell_print(sh, COREDUMP_LOG_PREFIX COREDUMP_LOG_BEGIN);

	while (true) {
		rc = log_rpc_get_crash_dump(offset, buffer, sizeof(buffer));
		if (rc <= 0) {
			break;
		}

		for (int i = 0; i < rc; i += COREDUMP_LOG_LINE_LEN) {
			bin2hex(&buffer[i], MIN(COREDUMP_LOG_LINE_LEN, rc - i), line, sizeof(line));
			shell_print(sh, COREDUMP_LOG_PREFIX "%s", line);
		}

		offset += (size_t)rc;
	}

	shell_print(sh, COREDUMP_LOG_PREFIX COREDUMP_LOG_END);

	if (rc) {
		shell_error(sh, "Error: %d", rc);
		return -ENOEXEC;
	}

	return 0;
}

static int cmd_log_rpc_crash_invalidate(const struct shell *sh, size_t argc, char *argv[])
{
	int rc;

	rc = log_rpc_invalidate_crash_dump();

	if (rc) {
		shell_error(sh, "Error: %d", rc);
		return -ENOEXEC;
	}

	return 0;
}

static int cmd_log_rpc_history_dump(const struct shell *sh, size_t argc, char *argv[])
{
	size_t offset = 0;
	size_t first_chunk_skip = 0; /* Skip "LH02" at start when text format */
	bool text_format = false;
	bool first_chunk = true;
	char buffer[CONFIG_NRF_PS_CLIENT_CRASH_DUMP_READ_BUFFER_SIZE];

	shell_print(sh, HISTORY_DUMP_PREFIX COREDUMP_LOG_BEGIN);

	while (true) {
		size_t rc = log_rpc_get_history_dump(offset, (uint8_t *)buffer, sizeof(buffer));

		if (rc == 0) {
			break;
		}

		if (first_chunk && rc >= HISTORY_DUMP_TEXT_MAGIC_LEN &&
		    memcmp(buffer, HISTORY_DUMP_TEXT_MAGIC, HISTORY_DUMP_TEXT_MAGIC_LEN) == 0) {
			text_format = true;
			first_chunk_skip = HISTORY_DUMP_TEXT_MAGIC_LEN;
		}
		first_chunk = false;

		if (text_format) {
			size_t to_show = rc - first_chunk_skip;

			if (to_show > 0) {
				shell_fprintf(sh, SHELL_NORMAL, "%.*s", (int)to_show,
					     (char *)buffer + first_chunk_skip);
			}
			first_chunk_skip = 0;
		}

		offset += rc;
	}

	shell_print(sh, HISTORY_DUMP_PREFIX COREDUMP_LOG_END);

	return 0;
}

static int cmd_log_rpc_history_dump_clear(const struct shell *sh, size_t argc, char *argv[])
{
	int rc;

	rc = log_rpc_clear_history_dump();

	if (rc) {
		shell_error(sh, "Error: %d", rc);
		return -ENOEXEC;
	}

	return 0;
}

static int cmd_log_rpc_echo(const struct shell *sh, size_t argc, char *argv[])
{
	int rc = 0;
	enum log_rpc_level level;

	level = (enum log_rpc_level)shell_strtol(argv[1], 10, &rc);

	if (rc) {
		shell_error(sh, "Invalid argument: %d", rc);
		return -EINVAL;
	}

	log_rpc_echo(level, argv[2]);

	return 0;
}

static int cmd_log_rpc_time(const struct shell *sh, size_t argc, char *argv[])
{
	int rc = 0;
	uint64_t time_us;

	if (strcmp(argv[1], "now") == 0) {
		time_us = k_ticks_to_us_near64(k_uptime_ticks());
	} else {
		time_us = shell_strtoull(argv[1], 10, &rc);
	}

	if (rc) {
		shell_error(sh, "Invalid argument: %d", rc);
		return -EINVAL;
	}

	log_rpc_set_time(time_us);

	return 0;
}

static int cmd_log_rpc_get_crash_info(const struct shell *sh, size_t argc, char *argv[])
{
	int rc;
	struct nrf_rpc_crash_info info;

	rc = log_rpc_get_crash_info(&info);
	if (rc) {
		shell_print(sh, "No coredump stored");

		return 0;
	}

	shell_print(sh, "uuid: %u", info.uuid);
	shell_print(sh, "reason: %u", info.reason);
	shell_print(sh, "PC: 0x%08x", info.pc);
	shell_print(sh, "LR: 0x%08x", info.lr);
	shell_print(sh, "SP: 0x%08x", info.sp);
	shell_print(sh, "XPSR: 0x%08x", info.xpsr);

	if (info.assert_line) {
		shell_print(sh, "ASSERT at %s:%u", info.assert_filename, info.assert_line);
	}

	return 0;
}

SHELL_STATIC_SUBCMD_SET_CREATE(crash_cmds,
			       SHELL_CMD_ARG(invalidate, NULL, "Invalidate crash dump",
					     cmd_log_rpc_crash_invalidate, 1, 0),
			       SHELL_SUBCMD_SET_END);

SHELL_STATIC_SUBCMD_SET_CREATE(history_dump_cmds,
			       SHELL_CMD_ARG(clear, NULL, "Clear history dump on remote",
					     cmd_log_rpc_history_dump_clear, 1, 0),
			       SHELL_SUBCMD_SET_END);

SHELL_STATIC_SUBCMD_SET_CREATE(
	log_rpc_cmds,
	SHELL_CMD_ARG(stream_level, NULL, "Set log streaming level <0-4>", cmd_log_rpc_stream_level,
		      2, 0),
	SHELL_CMD_ARG(history_level, NULL, "Set log history level <0-4>", cmd_log_rpc_history_level,
		      2, 0),
	SHELL_CMD_ARG(history_fetch, NULL, "Fetch log history", cmd_log_rpc_history_fetch, 1, 0),
	SHELL_CMD_ARG(history_stop_fetch, NULL, "Stop log history transfer <pause?>",
		      cmd_log_rpc_history_stop_fetch, 2, 0),
	SHELL_CMD_ARG(history_threshold, NULL, "Get or set history usage threshold [0-100]",
		      cmd_log_rpc_history_threshold, 1, 1),
	SHELL_CMD_ARG(history_usage, NULL, "Get current history usage",
		      cmd_log_rpc_history_usage_current, 1, 0),
	SHELL_CMD_ARG(crash, &crash_cmds, "Retrieve crash dump from remote", cmd_log_rpc_crash, 1,
		      0),
	SHELL_CMD_ARG(history_dump, &history_dump_cmds,
		     "Retrieve log history dump from remote (after crash)",
		     cmd_log_rpc_history_dump, 1, 0),
	SHELL_CMD_ARG(echo, NULL, "Generate log message on remote <0-4> <msg>", cmd_log_rpc_echo, 3,
		      0),
	SHELL_CMD_ARG(time, NULL, "Set current time <time_us|now>", cmd_log_rpc_time, 2, 0),
	SHELL_CMD_ARG(crash_info, NULL, "Fetch crash dump summary", cmd_log_rpc_get_crash_info, 1,
		      0),
	SHELL_SUBCMD_SET_END);

SHELL_CMD_ARG_REGISTER(log_rpc, &log_rpc_cmds, "RPC logging commands", NULL, 1, 0);
```

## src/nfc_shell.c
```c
/*
 * Copyright (c) 2024 Nordic Semiconductor ASA
 *
 * SPDX-License-Identifier: LicenseRef-Nordic-5-Clause
 */

#include <nfc_t2t_lib.h>
#include <nfc/ndef/msg.h>
#include <nfc/ndef/text_rec.h>

#include <zephyr/shell/shell.h>
#include <zephyr/sys/__assert.h>

#define NFC_MESSAGE_BUFFER 128

static uint8_t *default_message = "Hello World!";
static uint8_t *default_code = "en";

/* Buffer used to hold an NFC NDEF message. */
static uint8_t ndef_msg_buf[NFC_MESSAGE_BUFFER];

NFC_NDEF_MSG_DEF(msg_descr, 1);

static int message_encode(char *msg, uint32_t *length)
{
	int err;

	/* Create NFC NDEF text record description */
	NFC_NDEF_TEXT_RECORD_DESC_DEF(record, UTF_8, default_code, strlen(default_code), msg,
				      strlen(msg));

	/* Clear the message description. */
	nfc_ndef_msg_clear(&NFC_NDEF_MSG(msg_descr));

	/* Add text records to NDEF text message */
	err = nfc_ndef_msg_record_add(&NFC_NDEF_MSG(msg_descr), &NFC_NDEF_TEXT_RECORD_DESC(record));
	if (err < 0) {
		return err;
	}

	err = nfc_ndef_msg_encode(&NFC_NDEF_MSG(msg_descr), ndef_msg_buf, length);
	__ASSERT(*length <= NFC_MESSAGE_BUFFER, "message too long");

	return err;
}

static void nfc_callback(void *context, nfc_t2t_event_t event, const uint8_t *data,
			 size_t data_length)
{
	static const char *const event_str[] = {"none", "field_on", "field_off", "data_read",
						"stopped"};
	const struct shell *sh = (const struct shell *)context;

	switch (event) {
	case NFC_T2T_EVENT_NONE:
	case NFC_T2T_EVENT_FIELD_ON:
	case NFC_T2T_EVENT_FIELD_OFF:
	case NFC_T2T_EVENT_DATA_READ:
	case NFC_T2T_EVENT_STOPPED:
		shell_print(sh, "NFC T2T event: %s", event_str[event]);
		break;
	default:
		shell_print(sh, "Unknown NFC event");
	}
}

static int nfc_init_cmd(const struct shell *sh, size_t argc, char *argv[])
{
	int err = nfc_t2t_setup(nfc_callback, (void *)sh);
	uint32_t length = sizeof(ndef_msg_buf);

	if (err) {
		shell_print(sh, "Cannot setup NFC T2T library. err: %u", err);
		return -ENOEXEC;
	}

	if (message_encode(default_message, &length) < 0) {
		shell_print(sh, "Cannot encode message.");
		return -ENOEXEC;
	}

	/* Set created message as the NFC payload */
	if (nfc_t2t_payload_set(ndef_msg_buf, length) < 0) {
		shell_print(sh, "Cannot set payload.");
		return -ENOEXEC;
	}

	return 0;
}

static int nfc_release_cmd(const struct shell *sh, size_t argc, char *argv[])
{
	int err = nfc_t2t_done();

	if (err) {
		shell_print(sh, "Cannot release NFC. err: %u", err);
		return -ENOEXEC;
	}

	return 0;
}

static int nfc_start_cmd(const struct shell *sh, size_t argc, char *argv[])
{
	int err = nfc_t2t_emulation_start();

	if (err) {
		shell_print(sh, "Cannot activate NFC frontend. err: %u", err);
		return -ENOEXEC;
	}

	return 0;
}

static int nfc_stop_cmd(const struct shell *sh, size_t argc, char *argv[])
{
	int err = nfc_t2t_emulation_stop();

	if (err) {
		shell_print(sh, "Cannot deactivate NFC frontend. err: %u", err);
		return -ENOEXEC;
	}

	return 0;
}

static int nfc_set_msg_cmd(const struct shell *sh, size_t argc, char *argv[])
{
	uint32_t length = sizeof(ndef_msg_buf);

	if (message_encode(argv[1], &length) < 0) {
		shell_print(sh, "Cannot encode message.");
		return -ENOEXEC;
	}

	/* Set created message as the NFC payload */
	if (nfc_t2t_payload_set(ndef_msg_buf, length) < 0) {
		shell_print(sh, "Cannot set payload.");
		return -ENOEXEC;
	}

	return 0;
}

SHELL_STATIC_SUBCMD_SET_CREATE(
	nfc_cmds, SHELL_CMD_ARG(init, NULL, "Initialize NFC", nfc_init_cmd, 1, 0),
	SHELL_CMD_ARG(release, NULL, "Release NFC", nfc_release_cmd, 1, 0),
	SHELL_CMD_ARG(start, NULL, "Activate the NFC frontend", nfc_start_cmd, 1, 0),
	SHELL_CMD_ARG(stop, NULL, "Deactivate the NFC frontend", nfc_stop_cmd, 1, 0),
	SHELL_CMD_ARG(set_new_msg, NULL, "Set the new message to NFC payload", nfc_set_msg_cmd, 2,
		      0),
	SHELL_SUBCMD_SET_END);

SHELL_CMD_ARG_REGISTER(nfc, &nfc_cmds, "NFC demonstration commands", NULL, 1, 0);
```

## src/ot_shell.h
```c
/*
 * Copyright (c) 2024 Nordic Semiconductor ASA
 *
 * SPDX-License-Identifier: LicenseRef-Nordic-5-Clause
 */

#ifndef OT_SHELL_H_
#define OT_SHELL_H_

void ot_shell_server_restarted(void);

#endif
```
